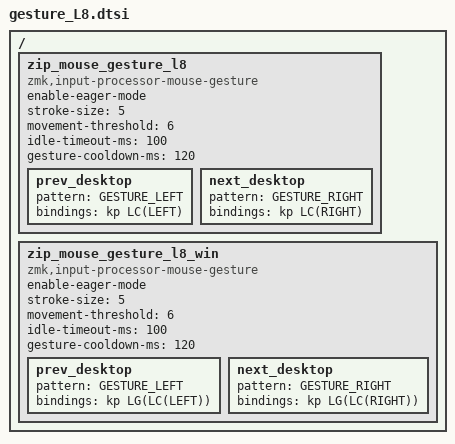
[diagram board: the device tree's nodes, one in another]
/ {
    zip_mouse_gesture_l8: zip_mouse_gesture_l8 {
        compatible = "zmk,input-processor-mouse-gesture";
        #input-processor-cells = <0>;
        enable-eager-mode;
        stroke-size = <5>;
        movement-threshold = <6>;
        idle-timeout-ms = <100>;
        gesture-cooldown-ms = <120>;

        prev_desktop { pattern = <GESTURE_LEFT>; bindings = <&kp LC(LEFT)>; };
        next_desktop { pattern = <GESTURE_RIGHT>; bindings = <&kp LC(RIGHT)>; };
    };

    zip_mouse_gesture_l8_win: zip_mouse_gesture_l8_win {
        compatible = "zmk,input-processor-mouse-gesture";
        #input-processor-cells = <0>;
        enable-eager-mode;
        stroke-size = <5>;
        movement-threshold = <6>;
        idle-timeout-ms = <100>;
        gesture-cooldown-ms = <120>;

        prev_desktop { pattern = <GESTURE_LEFT>; bindings = <&kp LG(LC(LEFT))>; };
        next_desktop { pattern = <GESTURE_RIGHT>; bindings = <&kp LG(LC(RIGHT))>; };
    };
};
